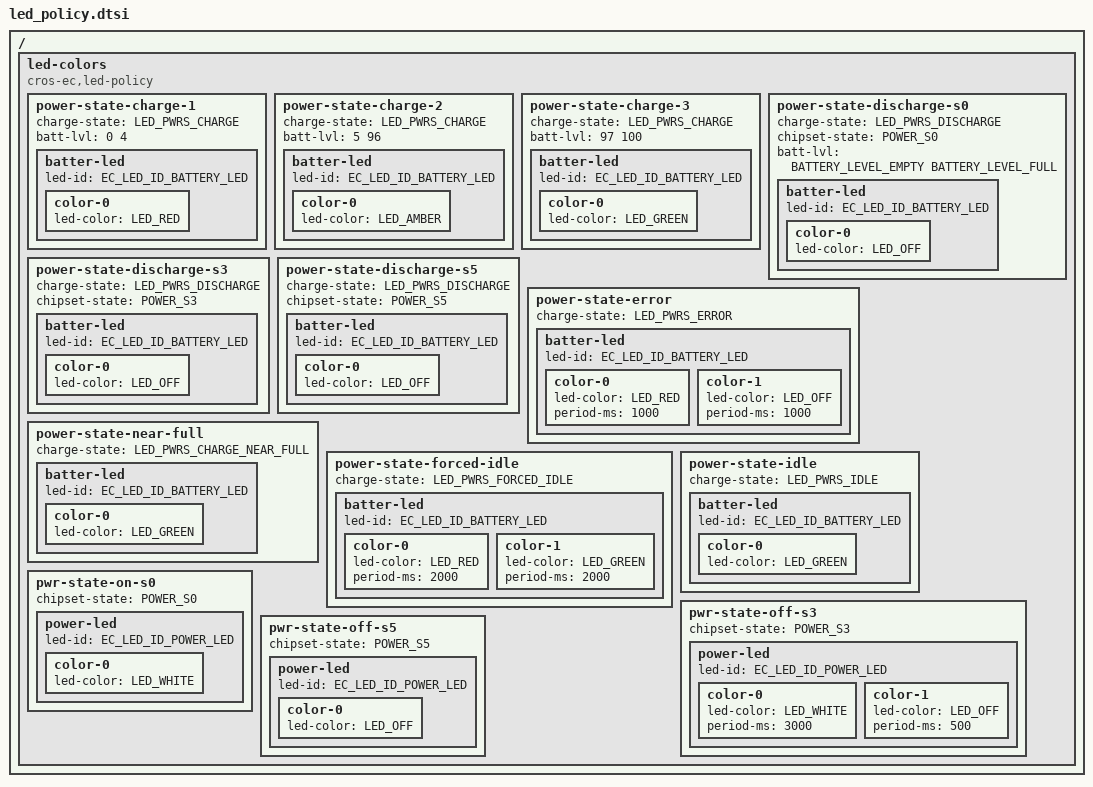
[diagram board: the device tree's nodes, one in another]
/* Copyright 2025 The ChromiumOS Authors
 * Use of this source code is governed by a BSD-style license that can be
 * found in the LICENSE file.
 */

#include <dt-bindings/battery.h>

/ {
	led-colors {
		compatible = "cros-ec,led-policy";

		power-state-charge-1 {
			charge-state = "LED_PWRS_CHARGE";
			batt-lvl = <0 4>;

			batter-led {
				led-id = "EC_LED_ID_BATTERY_LED";
				color-0 {
					led-color = "LED_RED";
				};
			};
		};

		power-state-charge-2 {
			charge-state = "LED_PWRS_CHARGE";
			batt-lvl = <5 96>;

			batter-led {
				led-id = "EC_LED_ID_BATTERY_LED";
				color-0 {
					led-color = "LED_AMBER";
				};
			};
		};

		power-state-charge-3 {
			charge-state = "LED_PWRS_CHARGE";
			batt-lvl = <97 100>;

			batter-led {
				led-id = "EC_LED_ID_BATTERY_LED";
				color-0 {
					led-color = "LED_GREEN";
				};
			};
		};

		power-state-discharge-s0 {
			charge-state = "LED_PWRS_DISCHARGE";
			chipset-state = "POWER_S0";
			/* Battery percent range (> Empty, <= Full) */
			batt-lvl = <BATTERY_LEVEL_EMPTY BATTERY_LEVEL_FULL>;

			batter-led {
				led-id = "EC_LED_ID_BATTERY_LED";
				color-0 {
					led-color = "LED_OFF";
				};
			};
		};

		power-state-discharge-s3 {
			charge-state = "LED_PWRS_DISCHARGE";
			chipset-state = "POWER_S3";

			batter-led {
				led-id = "EC_LED_ID_BATTERY_LED";
				color-0 {
					led-color = "LED_OFF";
				};
			};
		};

		power-state-discharge-s5 {
			charge-state = "LED_PWRS_DISCHARGE";
			chipset-state = "POWER_S5";

			batter-led {
				led-id = "EC_LED_ID_BATTERY_LED";
				color-0 {
					led-color = "LED_OFF";
				};
			};
		};

		power-state-error {
			charge-state = "LED_PWRS_ERROR";

			/* Red 1 sec, off 1 sec */
			batter-led {
				led-id = "EC_LED_ID_BATTERY_LED";
				color-0 {
					led-color = "LED_RED";
					period-ms = <1000>;
				};
				color-1 {
					led-color = "LED_OFF";
					period-ms = <1000>;
				};
			};
		};

		power-state-near-full {
			charge-state = "LED_PWRS_CHARGE_NEAR_FULL";

			batter-led {
				led-id = "EC_LED_ID_BATTERY_LED";
				color-0 {
					led-color = "LED_GREEN";
				};
			};
		};

		power-state-forced-idle {
			charge-state = "LED_PWRS_FORCED_IDLE";

			/* Red 2 sec, Green 2 sec */
			batter-led {
				led-id = "EC_LED_ID_BATTERY_LED";
				color-0 {
					led-color = "LED_RED";
					period-ms = <2000>;
				};
				color-1 {
					led-color = "LED_GREEN";
					period-ms = <2000>;
				};
			};
		};

		power-state-idle {
			charge-state = "LED_PWRS_IDLE";

			batter-led {
				led-id = "EC_LED_ID_BATTERY_LED";
				color-0 {
					led-color = "LED_GREEN";
				};
			};
		};

		pwr-state-on-s0 {
			chipset-state = "POWER_S0";

			power-led {
				led-id = "EC_LED_ID_POWER_LED";
				color-0 {
					led-color = "LED_WHITE";
				};
			};
		};

		pwr-state-off-s3 {
			chipset-state = "POWER_S3";

			power-led {
				led-id = "EC_LED_ID_POWER_LED";
				color-0 {
					led-color = "LED_WHITE";
					period-ms = <3000>;
				};
				color-1 {
					led-color = "LED_OFF";
					period-ms = <500>;
				};

			};
		};

		pwr-state-off-s5 {
			chipset-state = "POWER_S5";

			power-led {
				led-id = "EC_LED_ID_POWER_LED";
				color-0 {
					led-color = "LED_OFF";
				};
			};
		};
	};
};
